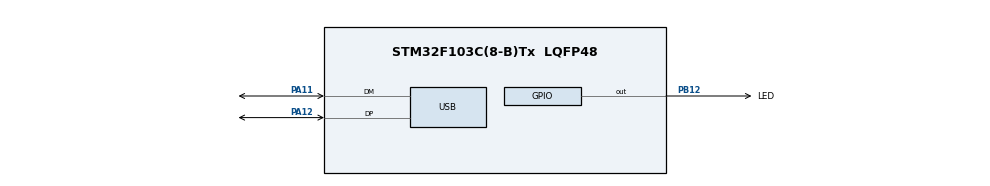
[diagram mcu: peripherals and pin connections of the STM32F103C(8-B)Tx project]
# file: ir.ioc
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FREERTOS.Tasks01=defaultTask,0,128,StartDefaultTask,Default,NULL,Dynamic,NULL,NULL;ledTask,0,128,ledTaskFUN,Default,NULL,Dynamic,NULL,NULL
FREERTOS.configTOTAL_HEAP_SIZE=10240
Mcu.Family=STM32F1
Mcu.Name=STM32F103C(8-B)Tx
Mcu.Package=LQFP48
NVIC.PriorityGroup=NVIC_PRIORITYGROUP_4
NVIC.TIM1_UP_IRQn=true\:0\:0\:false\:false\:true\:false\:false\:true
NVIC.TimeBase=TIM1_UP_IRQn
NVIC.TimeBaseIP=TIM1
NVIC.USB_LP_CAN1_RX0_IRQn=true\:5\:0\:false\:false\:true\:true\:false\:true
PA11.Mode=Device
PA11.Signal=USB_DM
PA12.Mode=Device
PA12.Signal=USB_DP
PA13.Mode=Serial_Wire
PA13.Signal=SYS_JTMS-SWDIO
PA14.Mode=Serial_Wire
PA14.Signal=SYS_JTCK-SWCLK
PB12.GPIO_Label=LED
PB12.GPIO_ModeDefaultOutputPP=GPIO_MODE_OUTPUT_PP
PB12.Signal=GPIO_Output
PD0-OSC_IN.Mode=HSE-External-Oscillator
PD0-OSC_IN.Signal=RCC_OSC_IN
PD1-OSC_OUT.Mode=HSE-External-Oscillator
PD1-OSC_OUT.Signal=RCC_OSC_OUT
ProjectManager.HeapSize=0x200
ProjectManager.StackSize=0x400
ProjectManager.TargetToolchain=EWARM V8.32
RCC.AHBFreq_Value=72000000
RCC.APB1CLKDivider=RCC_HCLK_DIV2
RCC.APB1Freq_Value=36000000
RCC.APB1TimFreq_Value=72000000
RCC.APB2Freq_Value=72000000
RCC.APB2TimFreq_Value=72000000
RCC.HCLKFreq_Value=72000000
RCC.PLLMUL=RCC_PLL_MUL9
RCC.PLLSourceVirtual=RCC_PLLSOURCE_HSE
RCC.SYSCLKFreq_VALUE=72000000
RCC.SYSCLKSource=RCC_SYSCLKSOURCE_PLLCLK
RCC.USBFreq_Value=48000000
RCC.USBPrescaler=RCC_USBCLKSOURCE_PLL_DIV1_5
USB_DEVICE.CLASS_NAME_FS=CDC
USB_DEVICE.VirtualMode=Cdc
USB_DEVICE.VirtualModeFS=Cdc_FS
VP_FREERTOS_VS_CMSIS_V1.Mode=CMSIS_V1
VP_SYS_VS_tim1.Mode=TIM1
VP_USB_DEVICE_VS_USB_DEVICE_CDC_FS.Mode=CDC_FS
board=custom

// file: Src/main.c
/* USER CODE BEGIN Header */
/**
  ******************************************************************************
  * @file           : main.c
  * @brief          : Main program body
  ******************************************************************************
  * @attention
  *
  * <h2><center>&copy; Copyright (c) 2019 STMicroelectronics.
  * All rights reserved.</center></h2>
  *
  * This software component is licensed by ST under Ultimate Liberty license
  * SLA0044, the "License"; You may not use this file except in compliance with
  * the License. You may obtain a copy of the License at:
  *                             www.st.com/SLA0044
  *
  ******************************************************************************
  */
/* USER CODE END Header */
#include "main.h"
#include "cmsis_os.h"
#include "usb_device.h"

osThreadId defaultTaskHandle;
osThreadId ledTaskHandle;

void SystemClock_Config( void );
static void MX_GPIO_Init( void );
void StartDefaultTask( void const *argument );
void ledTaskFUN( void const *argument );

int main( void )
{

    /* MCU Configuration--------------------------------------------------------*/

    /* Reset of all peripherals, Initializes the Flash interface and the Systick. */
    HAL_Init();

    /* Configure the system clock */
    SystemClock_Config();

    /* Initialize all configured peripherals */
    MX_GPIO_Init();

    /* Create the thread(s) */
    /* definition and creation of defaultTask */
    osThreadDef( defaultTask, StartDefaultTask, osPriorityNormal, 0, 128 );
    defaultTaskHandle = osThreadCreate( osThread( defaultTask ), NULL );

    /* definition and creation of ledTask */
    osThreadDef( ledTask, ledTaskFUN, osPriorityNormal, 0, 128 );
    ledTaskHandle = osThreadCreate( osThread( ledTask ), NULL );

    /* USER CODE BEGIN RTOS_THREADS */
    /* add threads, ... */
    extern void vRegisterSampleCLICommands( void );
    vRegisterSampleCLICommands();

    extern void vUARTCommandConsoleStart( uint16_t usStackSize, UBaseType_t uxPriority );
    vUARTCommandConsoleStart( 256, ( UBaseType_t ) osPriorityLow );
    /* USER CODE END RTOS_THREADS */

    /* Start scheduler */
    osKernelStart();

    /* We should never get here as control is now taken by the scheduler */
    /* Infinite loop */
    while( 1 )
    {

    }
}

void SystemClock_Config( void )
{
    RCC_OscInitTypeDef RCC_OscInitStruct = {0};
    RCC_ClkInitTypeDef RCC_ClkInitStruct = {0};
    RCC_PeriphCLKInitTypeDef PeriphClkInit = {0};

    /** Initializes the RCC Oscillators according to the specified parameters
    * in the RCC_OscInitTypeDef structure.
    */
    RCC_OscInitStruct.OscillatorType = RCC_OSCILLATORTYPE_HSE;
    RCC_OscInitStruct.HSEState = RCC_HSE_ON;
    RCC_OscInitStruct.HSEPredivValue = RCC_HSE_PREDIV_DIV1;
    RCC_OscInitStruct.HSIState = RCC_HSI_ON;
    RCC_OscInitStruct.PLL.PLLState = RCC_PLL_ON;
    RCC_OscInitStruct.PLL.PLLSource = RCC_PLLSOURCE_HSE;
    RCC_OscInitStruct.PLL.PLLMUL = RCC_PLL_MUL9;

    if( HAL_RCC_OscConfig( &RCC_OscInitStruct ) != HAL_OK )
    {
        Error_Handler();
    }

    /** Initializes the CPU, AHB and APB buses clocks
    */
    RCC_ClkInitStruct.ClockType = RCC_CLOCKTYPE_HCLK | RCC_CLOCKTYPE_SYSCLK
                                  | RCC_CLOCKTYPE_PCLK1 | RCC_CLOCKTYPE_PCLK2;
    RCC_ClkInitStruct.SYSCLKSource = RCC_SYSCLKSOURCE_PLLCLK;
    RCC_ClkInitStruct.AHBCLKDivider = RCC_SYSCLK_DIV1;
    RCC_ClkInitStruct.APB1CLKDivider = RCC_HCLK_DIV2;
    RCC_ClkInitStruct.APB2CLKDivider = RCC_HCLK_DIV1;

    if( HAL_RCC_ClockConfig( &RCC_ClkInitStruct, FLASH_LATENCY_2 ) != HAL_OK )
    {
        Error_Handler();
    }

    PeriphClkInit.PeriphClockSelection = RCC_PERIPHCLK_USB;
    PeriphClkInit.UsbClockSelection = RCC_USBCLKSOURCE_PLL_DIV1_5;

    if( HAL_RCCEx_PeriphCLKConfig( &PeriphClkInit ) != HAL_OK )
    {
        Error_Handler();
    }
}

static void MX_GPIO_Init( void )
{
    GPIO_InitTypeDef GPIO_InitStruct = {0};

    /* GPIO Ports Clock Enable */
    __HAL_RCC_GPIOD_CLK_ENABLE();
    __HAL_RCC_GPIOB_CLK_ENABLE();
    __HAL_RCC_GPIOA_CLK_ENABLE();

    /*Configure GPIO pin Output Level */
    HAL_GPIO_WritePin( LED_GPIO_Port, LED_Pin, GPIO_PIN_RESET );

    /*Configure GPIO pin : LED_Pin */
    GPIO_InitStruct.Pin = LED_Pin;
    GPIO_InitStruct.Mode = GPIO_MODE_OUTPUT_PP;
    GPIO_InitStruct.Pull = GPIO_NOPULL;
    GPIO_InitStruct.Speed = GPIO_SPEED_FREQ_LOW;
    HAL_GPIO_Init( LED_GPIO_Port, &GPIO_InitStruct );

}

void StartDefaultTask( void const *argument )
{
    /* init code for USB_DEVICE */
    MX_USB_DEVICE_Init();

    /* USER CODE BEGIN 5 */
    /* Infinite loop */
    for( ;; )
    {
        osDelay( 1 );
    }

    /* USER CODE END 5 */
}

void ledTaskFUN( void const *argument )
{
    /* USER CODE BEGIN ledTaskFUN */
    /* Infinite loop */
    for( ;; )
    {
        HAL_GPIO_TogglePin( LED_GPIO_Port, LED_Pin );
        osDelay( 500 );
    }

    /* USER CODE END ledTaskFUN */
}

void HAL_TIM_PeriodElapsedCallback( TIM_HandleTypeDef *htim )
{
    if( htim->Instance == TIM1 )
    {
        HAL_IncTick();
    }

}

void Error_Handler( void )
{
}

/************************ (C) COPYRIGHT STMicroelectronics *****END OF FILE****/

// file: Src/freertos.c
/* USER CODE BEGIN Header */
/**
  ******************************************************************************
  * File Name          : freertos.c
  * Description        : Code for freertos applications
  ******************************************************************************
  * @attention
  *
  * <h2><center>&copy; Copyright (c) 2019 STMicroelectronics.
  * All rights reserved.</center></h2>
  *
  * This software component is licensed by ST under Ultimate Liberty license
  * SLA0044, the "License"; You may not use this file except in compliance with
  * the License. You may obtain a copy of the License at:
  *                             www.st.com/SLA0044
  *
  ******************************************************************************
  */
/* USER CODE END Header */

#include "FreeRTOS.h"
#include "task.h"
#include "main.h"

/* GetIdleTaskMemory prototype (linked to static allocation support) */
void vApplicationGetIdleTaskMemory( StaticTask_t **ppxIdleTaskTCBBuffer, StackType_t **ppxIdleTaskStackBuffer, uint32_t *pulIdleTaskStackSize );

/* USER CODE BEGIN GET_IDLE_TASK_MEMORY */
static StaticTask_t xIdleTaskTCBBuffer;
static StackType_t xIdleStack[configMINIMAL_STACK_SIZE];

void vApplicationGetIdleTaskMemory( StaticTask_t **ppxIdleTaskTCBBuffer, StackType_t **ppxIdleTaskStackBuffer, uint32_t *pulIdleTaskStackSize )
{
    *ppxIdleTaskTCBBuffer = &xIdleTaskTCBBuffer;
    *ppxIdleTaskStackBuffer = &xIdleStack[0];
    *pulIdleTaskStackSize = configMINIMAL_STACK_SIZE;
    /* place for user code */
}
/* USER CODE END GET_IDLE_TASK_MEMORY */

/************************ (C) COPYRIGHT STMicroelectronics *****END OF FILE****/
